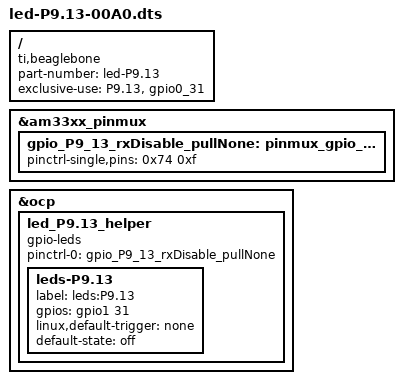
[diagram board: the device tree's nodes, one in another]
/*
* Easy gpio mux control of "P9.13" ("gpio0_31")
*/
/dts-v1/;
/plugin/;

/ {
	compatible = "ti,beaglebone", "ti,beaglebone-black";

	/* identification */
	part-number = "led-P9.13";
	/* version = "00A0"; */

	/* state the resources this cape uses */
	exclusive-use =
		/* the pin header uses */
		"P9.13",

		/* the hardware IP uses */
		"gpio0_31";
	
	
	/* rxDisable_pullNone state */
	fragment@0 {
		target = <&am33xx_pinmux>;
		__overlay__ {
			gpio_P9_13_rxDisable_pullNone: pinmux_gpio_P9.13_rxDisable_pullNone {
				pinctrl-single,pins = <
					0x74 0xf
				>;
			};
		};
	};

	fragment@1 {
		target = <&ocp>;
		__overlay__ {
			led_P9.13_helper {
				compatible = "gpio-leds";
				pinctrl-names = "default";
				pinctrl-0 = <&gpio_P9_13_rxDisable_pullNone>;
				
				leds-P9.13 {
					label = "leds:P9.13";
					gpios = <&gpio1 31 0>;
					linux,default-trigger = "none";
					default-state = "off";
				};
			};
			
		};
	};

};
